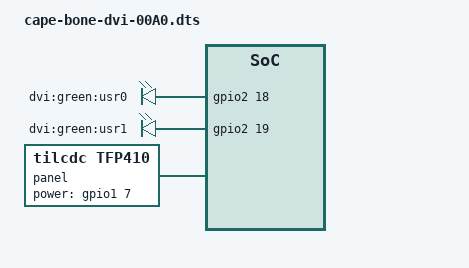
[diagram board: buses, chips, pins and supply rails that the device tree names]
/*
 * Copyright (C) 2012 Texas Instruments Incorporated - http://www.ti.com/
 *
 * This program is free software; you can redistribute it and/or modify
 * it under the terms of the GNU General Public License version 2 as
 * published by the Free Software Foundation.
 */
/dts-v1/;
/plugin/;

/ {
	compatible = "ti,beaglebone", "ti,beaglebone-black";

	/* identification */
	part-number = "BB-BONE-DVID-01";
	version = "00A0";

	fragment@0 {
		target = <&am33xx_pinmux>;
		__overlay__ {

			bone_dvi_cape_led_pins: pinmux_bone_dvi_cape_led_pins {
				pinctrl-single,pins = <
					0x48 0x07	/* gpmc_a2.gpio1_18, OUTPUT | MODE7 */
					0x4c 0x07	/* gpmc_a3.gpio1_19, OUTPUT | MODE7 */
				>;
			};

			bone_dvi_cape_dvi_00A0_pins: pinmux_bone_dvi_cape_dvi_00A0_pins {
				pinctrl-single,pins = <
					0x1c 0x07	/* gpmc_ad7.gpio1_7, OUTPUT | MODE7 - DVIPDn */

					0xa0 0x08	/* lcd_data0.lcd_data0, OMAP_MUX_MODE0 | AM33XX_PIN_OUTPUT | AM33XX_PULL_DISA */
					0xa4 0x08	/* lcd_data1.lcd_data1, OMAP_MUX_MODE0 | AM33XX_PIN_OUTPUT | AM33XX_PULL_DISA */
					0xa8 0x08	/* lcd_data2.lcd_data2, OMAP_MUX_MODE0 | AM33XX_PIN_OUTPUT | AM33XX_PULL_DISA */
					0xac 0x08	/* lcd_data3.lcd_data3, OMAP_MUX_MODE0 | AM33XX_PIN_OUTPUT | AM33XX_PULL_DISA */
					0xb0 0x08	/* lcd_data4.lcd_data4, OMAP_MUX_MODE0 | AM33XX_PIN_OUTPUT | AM33XX_PULL_DISA */
					0xb4 0x08	/* lcd_data5.lcd_data5, OMAP_MUX_MODE0 | AM33XX_PIN_OUTPUT | AM33XX_PULL_DISA */
					0xb8 0x08	/* lcd_data6.lcd_data6, OMAP_MUX_MODE0 | AM33XX_PIN_OUTPUT | AM33XX_PULL_DISA */
					0xbc 0x08	/* lcd_data7.lcd_data7, OMAP_MUX_MODE0 | AM33XX_PIN_OUTPUT | AM33XX_PULL_DISA */
					0xc0 0x08	/* lcd_data8.lcd_data8, OMAP_MUX_MODE0 | AM33XX_PIN_OUTPUT | AM33XX_PULL_DISA */
					0xc4 0x08	/* lcd_data9.lcd_data9, OMAP_MUX_MODE0 | AM33XX_PIN_OUTPUT | AM33XX_PULL_DISA */
					0xc8 0x08	/* lcd_data10.lcd_data10, OMAP_MUX_MODE0 | AM33XX_PIN_OUTPUT | AM33XX_PULL_DISA */
					0xcc 0x08	/* lcd_data11.lcd_data11, OMAP_MUX_MODE0 | AM33XX_PIN_OUTPUT | AM33XX_PULL_DISA */
					0xd0 0x08	/* lcd_data12.lcd_data12, OMAP_MUX_MODE0 | AM33XX_PIN_OUTPUT | AM33XX_PULL_DISA */
					0xd4 0x08	/* lcd_data13.lcd_data13, OMAP_MUX_MODE0 | AM33XX_PIN_OUTPUT | AM33XX_PULL_DISA */
					0xd8 0x08	/* lcd_data14.lcd_data14, OMAP_MUX_MODE0 | AM33XX_PIN_OUTPUT | AM33XX_PULL_DISA */
					0xdc 0x08	/* lcd_data15.lcd_data15, OMAP_MUX_MODE0 | AM33XX_PIN_OUTPUT | AM33XX_PULL_DISA */
					0xe0 0x00	/* lcd_vsync.lcd_vsync, OMAP_MUX_MODE0 | AM33XX_PIN_OUTPUT */
					0xe4 0x00	/* lcd_hsync.lcd_hsync, OMAP_MUX_MODE0 | AM33XX_PIN_OUTPUT */
					0xe8 0x00	/* lcd_pclk.lcd_pclk, OMAP_MUX_MODE0 | AM33XX_PIN_OUTPUT */
					0xec 0x00	/* lcd_ac_bias_en.lcd_ac_bias_en, OMAP_MUX_MODE0 | AM33XX_PIN_OUTPUT */
				>;
			};
		};
	};

	fragment@1 {
		target = <&ocp>;
		__overlay__ {

			/* avoid stupid warning */
			#address-cells = <1>;
			#size-cells = <1>;

			gpio-leds-cape-dvi {
				compatible = "gpio-leds";
				pinctrl-names = "default";
				pinctrl-0 = <&bone_dvi_cape_led_pins>;

				dvi-led0 {
					label = "dvi:green:usr0";
					gpios = <&gpio2 18 0>;
					linux,default-trigger = "heartbeat";
					default-state = "off";
				};

				dvi-led1 {
					label = "dvi:green:usr1";
					gpios = <&gpio2 19 0>;
					linux,default-trigger = "mmc0";
					default-state = "off";
				};
			};

			/* use the DVI panel now */
			panel {
				compatible = "tilcdc,tfp410";
				pinctrl-names = "default";
				pinctrl-0 = <&bone_dvi_cape_dvi_00A0_pins>;
				ti,power-gpio = <&gpio1 7 0x0>;
				i2c = <&i2c2>;
			};

			fb {
				compatible = "ti,am33xx-tilcdc";
				reg = <0x4830e000 0x1000>;
				interrupt-parent = <&intc>;
				interrupts = <36>;
				ti,hwmods = "lcdc";
			};

		};
	};
};
